# STM32F101 register map
File version: 1.2
CPU: CM3 r1p1, little endian, no MPU, no FPU, 4 interrupt priority bits
Registers are 32-bit, read-write, reset 0x0 unless marked. A register's access mark holds for its fields unless they carry their own. Offsets are from the block's base; [hi:lo] are bit positions.

## OTG_FS_PWRCLK — USB on the go full speed
Base 0x50000E00
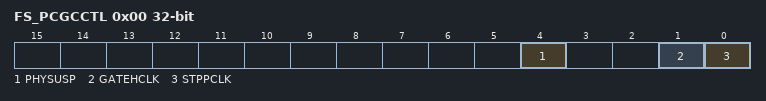
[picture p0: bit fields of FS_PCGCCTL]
0x00 FS_PCGCCTL — OTG_FS power and clock gating control register
  [4] PHYSUSP — PHY Suspended
  [1] GATEHCLK
  [0] STPPCLK — Stop PHY clock

## ETHERNET_MMC — Ethernet: MAC management counters
Base 0x40028100
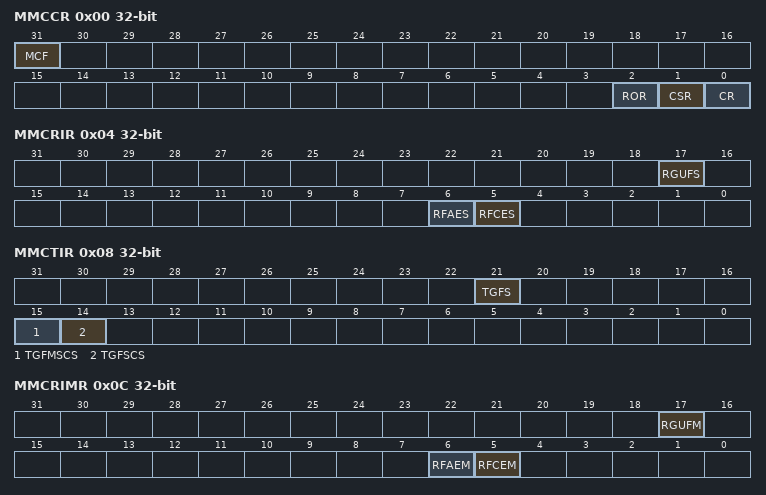
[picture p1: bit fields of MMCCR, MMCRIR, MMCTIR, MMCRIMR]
0x00 MMCCR — Ethernet MMC control register (ETH_MMCCR)
  [31] MCF — MMC counter freeze
  [2] ROR — Reset on read
  [1] CSR — Counter stop rollover
  [0] CR — Counter reset
0x04 MMCRIR — Ethernet MMC receive interrupt register (ETH_MMCRIR)
  [17] RGUFS — Received Good Unicast Frames Status
  [6] RFAES — Received frames alignment error status
  [5] RFCES — Received frames CRC error status
0x08 MMCTIR — Ethernet MMC transmit interrupt register (ETH_MMCTIR)
  [21] TGFS — Transmitted good frames status
  [15] TGFMSCS — Transmitted good frames more single collision status
  [14] TGFSCS — Transmitted good frames single collision status
0x0C MMCRIMR — Ethernet MMC receive interrupt mask register (ETH_MMCRIMR)
  [17] RGUFM — Received good unicast frames mask
  [6] RFAEM — Received frames alignment error mask
  [5] RFCEM — Received frame CRC error mask
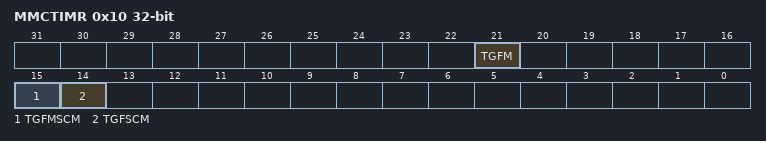
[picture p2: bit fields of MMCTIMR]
0x10 MMCTIMR — Ethernet MMC transmit interrupt mask register (ETH_MMCTIMR)
  [21] TGFM — Transmitted good frames mask
  [15] TGFMSCM — Transmitted good frames more single collision mask
  [14] TGFSCM — Transmitted good frames single collision mask
0x4C MMCTGFSCCR ro — Ethernet MMC transmitted good frames after a single collision counter
  [31:0] TGFSCC — Transmitted good frames after a single collision counter
0x50 MMCTGFMSCCR ro — Ethernet MMC transmitted good frames after more than a single collision
  [31:0] TGFMSCC — Transmitted good frames after more than a single collision counter
0x68 MMCTGFCR ro — Ethernet MMC transmitted good frames counter register
  [31:0] TGFC — Transmitted good frames counter
0x94 MMCRFCECR ro — Ethernet MMC received frames with CRC error counter register
  [31:0] RFCFC — Received frames with CRC error counter
0x98 MMCRFAECR ro — Ethernet MMC received frames with alignment error counter register
  [31:0] RFAEC — Received frames with alignment error counter
0xC4 MMCRGUFCR ro — MMC received good unicast frames counter register
  [31:0] RGUFC — Received good unicast frames counter

## ETHERNET_PTP — Ethernet: Precision time protocol
Base 0x40028700
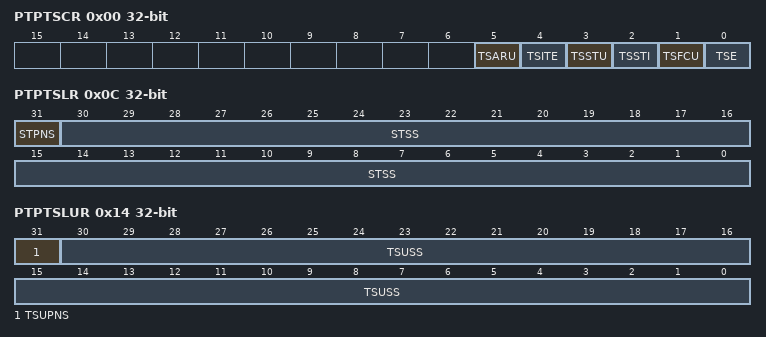
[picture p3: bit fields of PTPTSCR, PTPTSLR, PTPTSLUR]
0x00 PTPTSCR — Ethernet PTP time stamp control register (ETH_PTPTSCR)
  [5] TSARU — Time stamp addend register update
  [4] TSITE — Time stamp interrupt trigger enable
  [3] TSSTU — Time stamp system time update
  [2] TSSTI — Time stamp system time initialize
  [1] TSFCU — Time stamp fine or coarse update
  [0] TSE — Time stamp enable
0x04 PTPSSIR — Ethernet PTP subsecond increment register
  [7:0] STSSI — System time subsecond increment
0x08 PTPTSHR ro — Ethernet PTP time stamp high register
  [31:0] STS — System time second
0x0C PTPTSLR ro — Ethernet PTP time stamp low register (ETH_PTPTSLR)
  [31] STPNS — System time positive or negative sign
  [30:0] STSS — System time subseconds
0x10 PTPTSHUR — Ethernet PTP time stamp high update register
  [31:0] TSUS — Time stamp update second
0x14 PTPTSLUR — Ethernet PTP time stamp low update register (ETH_PTPTSLUR)
  [31] TSUPNS — Time stamp update positive or negative sign
  [30:0] TSUSS — Time stamp update subseconds
0x18 PTPTSAR — Ethernet PTP time stamp addend register
  [31:0] TSA — Time stamp addend
0x1C PTPTTHR — Ethernet PTP target time high register
  [31:0] TTSH — Target time stamp high
0x20 PTPTTLR — Ethernet PTP target time low register
  [31:0] TTSL — Target time stamp low

## ETHERNET_DMA — Ethernet: DMA controller operation
Base 0x40029000
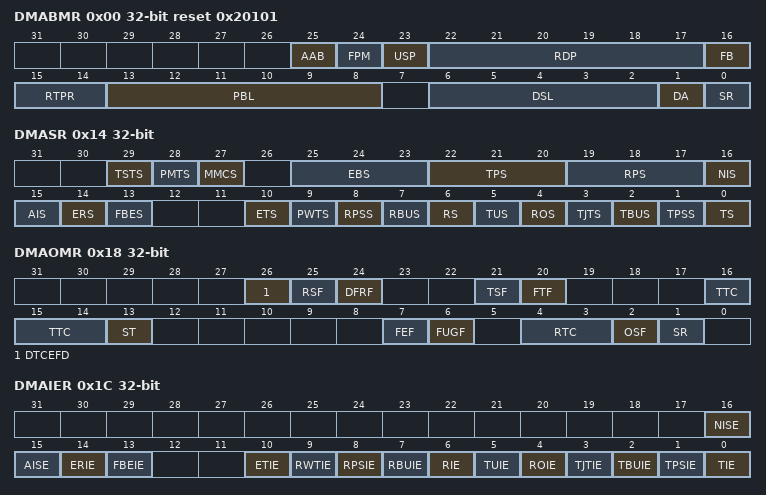
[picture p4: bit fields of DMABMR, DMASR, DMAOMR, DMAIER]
0x00 DMABMR reset 0x20101 — Ethernet DMA bus mode register
  [25] AAB — Address-aligned beats
  [24] FPM — 4xPBL mode
  [23] USP — Use separate PBL
  [22:17] RDP — Rx DMA PBL
  [16] FB — Fixed burst
  [15:14] RTPR — Rx Tx priority ratio
  [13:8] PBL — Programmable burst length
  [6:2] DSL — Descriptor skip length
  [1] DA — DMA Arbitration
  [0] SR — Software reset
0x04 DMATPDR — Ethernet DMA transmit poll demand register
  [31:0] TPD — Transmit poll demand
0x08 DMARPDR — EHERNET DMA receive poll demand register
  [31:0] RPD — Receive poll demand
0x0C DMARDLAR — Ethernet DMA receive descriptor list address register
  [31:0] SRL — Start of receive list
0x10 DMATDLAR — Ethernet DMA transmit descriptor list address register
  [31:0] STL — Start of transmit list
0x14 DMASR access per field — Ethernet DMA status register
  [29] TSTS ro — Time stamp trigger status
  [28] PMTS ro — PMT status
  [27] MMCS ro — MMC status
  [25:23] EBS ro — Error bits status
  [22:20] TPS ro — Transmit process state
  [19:17] RPS ro — Receive process state
  [16] NIS rw — Normal interrupt summary
  [15] AIS rw — Abnormal interrupt summary
  [14] ERS rw — Early receive status
  [13] FBES rw — Fatal bus error status
  [10] ETS rw — Early transmit status
  [9] PWTS rw — Receive watchdog timeout status
  [8] RPSS rw — Receive process stopped status
  [7] RBUS rw — Receive buffer unavailable status
  [6] RS rw — Receive status
  [5] TUS rw — Transmit underflow status
  [4] ROS rw — Receive overflow status
  [3] TJTS rw — Transmit jabber timeout status
  [2] TBUS rw — Transmit buffer unavailable status
  [1] TPSS rw — Transmit process stopped status
  [0] TS rw — Transmit status
0x18 DMAOMR — Ethernet DMA operation mode register
  [26] DTCEFD, [25] RSF, [24] DFRF, [21] TSF, [20] FTF, [16:14] TTC, [13] ST, [7] FEF, [6] FUGF, [4:3] RTC, [2] OSF, [1] SR
0x1C DMAIER — Ethernet DMA interrupt enable register
  [16] NISE — Normal interrupt summary enable
  [15] AISE — Abnormal interrupt summary enable
  [14] ERIE — Early receive interrupt enable
  [13] FBEIE — Fatal bus error interrupt enable
  [10] ETIE — Early transmit interrupt enable
  [9] RWTIE — receive watchdog timeout interrupt enable
  [8] RPSIE — Receive process stopped interrupt enable
  [7] RBUIE — Receive buffer unavailable interrupt enable
  [6] RIE — Receive interrupt enable
  [5] TUIE — Underflow interrupt enable
  [4] ROIE — Overflow interrupt enable
  [3] TJTIE — Transmit jabber timeout interrupt enable
  [2] TBUIE — Transmit buffer unavailable interrupt enable
  [1] TPSIE — Transmit process stopped interrupt enable
  [0] TIE — Transmit interrupt enable
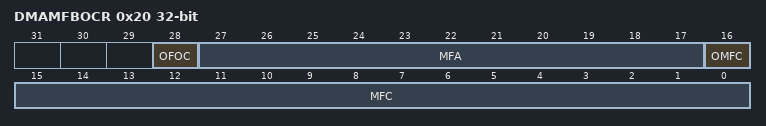
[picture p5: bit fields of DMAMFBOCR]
0x20 DMAMFBOCR ro — Ethernet DMA missed frame and buffer overflow counter register
  [28] OFOC — Overflow bit for FIFO overflow counter
  [27:17] MFA — Missed frames by the application
  [16] OMFC — Overflow bit for missed frame counter
  [15:0] MFC — Missed frames by the controller
0x48 DMACHTDR ro — Ethernet DMA current host transmit descriptor register
  [31:0] HTDAP — Host transmit descriptor address pointer
0x4C DMACHRDR ro — Ethernet DMA current host receive descriptor register
  [31:0] HRDAP — Host receive descriptor address pointer
0x50 DMACHTBAR ro — Ethernet DMA current host transmit buffer address register
  [31:0] HTBAP — Host transmit buffer address pointer
0x54 DMACHRBAR ro — Ethernet DMA current host receive buffer address register
  [31:0] HRBAP — Host receive buffer address pointer
